# iND83216 register map
Vendor: Indiemicro; Series: RealplumTiny; File version: 1.00
CPU: CM0 r0p1, selectable endian, no MPU, no FPU, 4 interrupt priority bits
Registers are 32-bit, read-write, no defined reset value unless marked. A register's access mark holds for its fields unless they carry their own. Offsets are from the block's base; [hi:lo] are bit positions; {n}, {i} and the like mark numbered series.

## SAR_CTRL — SAR ADC Interface registers
Base 0x50013400; register names take the prefix SAR_CTRL_
0x00 DATA1 — Data Out of CH1
  [15:0] DATA1 ro — The result of ADC conversion of CH1(in 2's-complement)
0x04 DATA2 — Data Out of CH2
  [15:0] DATA2 ro — The result of ADC conversion of CH2(in 2's-complement)
0x08 DATA3 — Data Out of CH3
  [15:0] DATA3 ro — The result of ADC conversion of CH3(in 2's-complement)
0x0C DATA4 — Data Out of CH4
  [15:0] DATA4 ro — The result of ADC conversion of CH4(in 2's-complement)
0x10 DATA5 — Data Out of CH5
  [15:0] DATA5 ro — The result of ADC conversion of CH5(in 2's-complement)
0x14 DATA6 — Data Out of CH6
  [15:0] DATA6 ro — The result of ADC conversion of CH6(in 2's-complement)
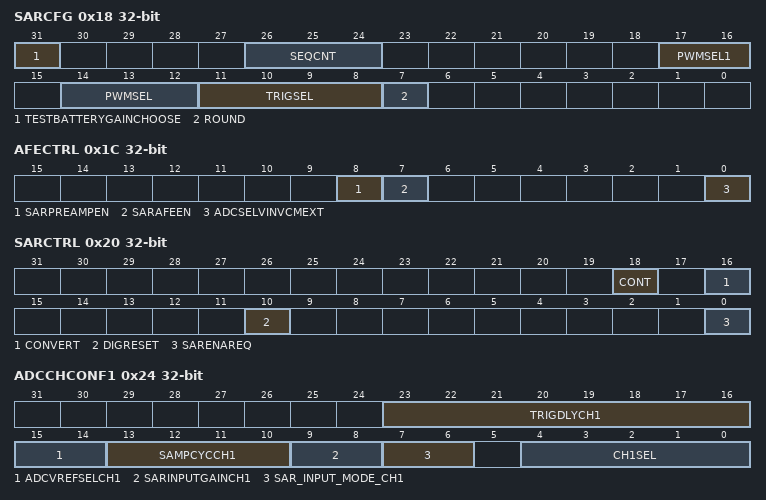
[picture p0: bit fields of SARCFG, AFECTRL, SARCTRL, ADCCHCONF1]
0x18 SARCFG — SAR Configuration Register
  [31] TESTBATTERYGAINCHOOSE — VBAT Gain Select. 0: gain=1/14, vbat max 30V/14=2.14v, under ADC vref=2v 1: gain=1/28, vbat max 30V/28=1.07v, under ADC vref=1.2v
  [26:24] SEQCNT — Channel Sequence count. Selects the sequence of channels to be converted 0x1: CH1 only0x2: CH1->CH20x3: CH1->CH2->CH30x4: CH1->CH2->CH3->CH40x5: CH1 to CH5 sequentially0x6: CH1 to CH6 sequentially
  [17:16] PWMSEL1 — PWM Period Trigger Signal Selects. Selects the PWM Period trigger Source.0x0: Triggered by PWM Period0x1: Triggered by PWM Aux counter0 Period0x2: Triggered by PWM Aux counter1 Period
  [14:12] PWMSEL — PWM Edge Trigger Signal Selects. Selects the PWM Edge trigger Source.0x0: Triggered by PWM0 edge0x1: Triggered by PWM1 edge0x2: Triggered by PWM2 edge0x3: Triggered by PWM AUX0 edge0x4: Triggered by PWM AUX1 edge
  [11:8] TRIGSEL — SAR Converion Trigger Selects. Selects the trigger condition of SAR ADC. Don't change the bits during an ADC conversion sequence is ongoing.0x1: Triggered through writing 1 to conversion bit.0x2: Triggered by PWM posedge.0x4: Triggered by PWM negedge.0x8: Triggered by PWM period.
  [7] ROUND — ADC round enable. Enable ADC round.0x0: No round.0x1: Negative code+1
0x1C AFECTRL — SAR AFE Control
  [8] SARPREAMPEN — adc pre-amp enable. 0:disable, 1:enable
  [7] SARAFEEN — ADC AFE Enable. adc afe enable. If vinp, vinn and vin vcm all choose external, adc afe should be disabled: adc_adc_en=0, otherwise, adc afe must be enabled: adc_afe_en=1.
  [0] ADCSELVINVCMEXT — Select External Inputs to ADC. choose ADC input common voltage. 0: choose internal vin_vcm, equals to (vinp+vinn)/2; 1: choose external vin_vcm, for PN detect.
0x20 SARCTRL — SAR ADC Control
  [18] CONT — Continuous Conversion Enable. If this bit has been set before an ADC conversion sequence trigged by CONVERT bit or PWM signals, the sequence will be treated as a sequential conversion, rather than a single conversion.
  [16] CONVERT — ADC START/STATUS Register. If SOFTWARE trigger source is selected, set to start a conversion, If HARDWARE trigger source is selected, write to this field will be ignored. Read 1 indicates ADC conversion is active; Read 0 indicates ADC is in idle state.
  [10] DIGRESET wo — SAR Digital Part Reset. Resets SAR digital parts.Autoclear: includes a synchronous reset signal which clears the register on the cycle following write.
  [0] SARENAREQ — SAR ADC Enable. Set to enable the SAR analog & digital part
0x24 ADCCHCONF1 — ADC Channel1 Configuration
  [23:16] TRIGDLYCH1 — Channel1 trigger delay. setting trigger delay time from 0 to 255 sar clock cycles. For PN-detect, trigger delay MUST >= 2us.
  [15:14] ADCVREFSELCH1 — Channel1 adc vref select. 0x0: adc_vref = vbg 0x1: adc_vref = 2.0V 0x2: adc_vref = VDD_3V3 0x3: adc_vref = VDD_3V3 if configure Vref from 2V to vbg, you can observe the change after start adc ,
  [13:10] SAMPCYCCH1 — Channel1 Sample cycle. setting sampling time from 1 to 16 sar clock cycles.0x0: 1 Cycle0x1: 2 Cycles0x2: 3 Cycles ...0xf: 16 Cycles
  [9:8] SARINPUTGAINCH1 — ADC Channel1 input gain. 2'b00: 18/32 2'b01: 26/32 2'b1x: 31/32
  [7:6] SAR_INPUT_MODE_CH1 — CH1 AFE Input Modes. ADC AFE Input Modes for Channel1.0x0: All external.0x1: VINP buffered, VINN external.0x2: VINN buffered, VINP external.0x3: Both VINP & VINN buffered.
  [4:0] CH1SEL — Channel1 Selection. Channel1 Selects.0x1: adc_vinp=adc_refp , adc_vinn=adc_refp (all shot to adc_ref(2.4V) for adc channel offset K)0x2: adc_vinp=adc_refp , adc_vinn=vref_gnd (for adc channel +gain error K)0x3: adc_vinp=vref_gnd , adc_vinn=adc_refp (for adc channel -gain error K)0x4: adc_vinp=TempSensor , adc_vinn=vref_gnd0x5: adc_vinp=VDD_1V5 , adc_vinn=vref_gnd0x6: adc_vinp=VDD_3V3 , adc_vinn=vref_gnd. If IOCTRL.GPIOCONSEL is set when measuring this channel, IOCTRL.GPIOCONREG[0] must also set.0x7: adc_vinp=VDD_PRE5V (1/4) , adc_vinn=vref_gnd. If IOCTRL.GPIOCONSEL is set when measuring this channel, IOCTRL.GPIOCONREG[2] must also set.0x8: adc_vinp=VBAT ACCURATE (gain selected by TEST_BATTERY_GAIN_CHOOSE), adc_vinn=vref_gnd0x9: adc_vinp=LED0 , adc_vinn=vref_gnd.(for short gnd detecting)0xa: adc_vinp=LED1 , adc_vinn=vref_gnd.(for short gnd detecting)0xb: adc_vinp=LED2 , adc_vinn=vref_gnd.(for short gnd detecting)0xc: adc_vinp=PA , adc_vinn=vref_gnd0xd: adc_vinp=SWD , adc_vinn=vref_gnd0xe: adc_vinp=SWC , adc_vinn=vref_gnd0xf: adc_vinp=VBAT , adc_vinn=LED00x10: adc_vinp=VBAT , adc_vinn=LED10x11: adc_vinp=VBAT , adc_vinn=LED2
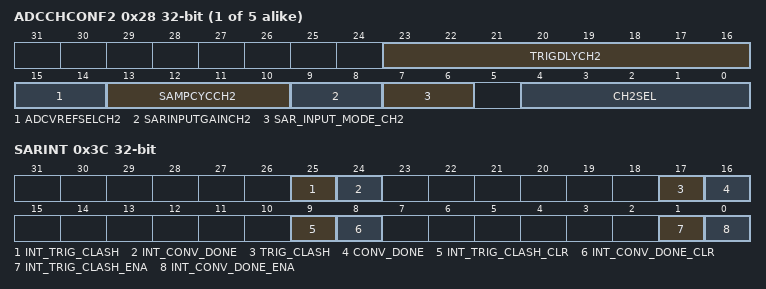
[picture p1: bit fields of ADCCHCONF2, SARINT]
{0x20+4i} ADCCHCONF{i} (i=2..6) — ADC Channel{i} Configuration
  [23:16] TRIGDLYCH{i} — Channel{i} trigger delay. refer to TRIG_DLY_CH1
  [15:14] ADCVREFSELCH{i} — Channel{i} adc vref select. refer to ADC_VREF_SEL_CH1 for defination
  [13:10] SAMPCYCCH{i} — Channel{i} Sample cycle. refer to SAMPCYC_CH1 for defination
  [9:8] SARINPUTGAINCH{i} — ADC Channel{i} input gain. refer to SAR_INPUT_GAIN_CH1 for defination
  [7:6] SAR_INPUT_MODE_CH{i} — CH{i} AFE Input Modes. refer to SAR_INPUT_MODE_CH1 for defination
  [4:0] CH{i}SEL — Channel{i} Selection. refer to CH1_SEL for defination.
0x3C SARINT — SAR Interrupts
  [25] INT_TRIG_CLASH ro — Trigger Clash Interrupt. Set by the SAR when TRIG_CLASH is high and INT_TRIG_CLASH_ENA is set
  [24] INT_CONV_DONE ro — Convert Done Interrupt. Set by the SAR when an convert done occurs
  [17] TRIG_CLASH ro — Trigger Clash. Set by the SAR when new trigger issued when previous has not finished.
  [16] CONV_DONE ro — Convert Done. Set by the SAR when an conversion is done.
  [9] INT_TRIG_CLASH_CLR wo — Trigger Clash Interrupt Clear.
  [8] INT_CONV_DONE_CLR wo — Convert Done Interrupt Clear. Autoclear: includes a synchronous reset signal which clears the register on the cycle following write.
  [1] INT_TRIG_CLASH_ENA — Trigger Clash Interrupt Enable.
  [0] INT_CONV_DONE_ENA — Convert Done Interrupt Enable.
0x40 SARCLKDIV — SAR CLOCK DIVIDE
  [7:0] SARCLKDIV — SAR CLOCK DIVIDE. Divide ration is (SAR_CLK_DIV+1)
